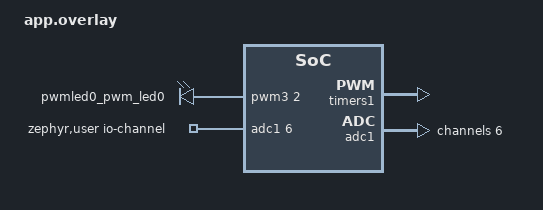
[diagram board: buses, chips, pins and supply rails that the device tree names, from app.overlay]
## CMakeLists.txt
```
cmake_minimum_required(VERSION 3.20.0)

find_package(Zephyr REQUIRED)

project(
  stm32_h7s78
  DESCRIPTION "a simple stm32h7s78_dk project ported from stm32_h743zi"
  VERSION 1
  LANGUAGES C
)

file(GLOB APP_SOURCES src/*.c)

target_sources(app PRIVATE ${APP_SOURCES})

add_subdirectory(ui)

target_link_libraries(app PRIVATE ui)

target_include_directories(app PRIVATE include)
```

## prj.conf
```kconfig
CONFIG_LV_Z_MEM_POOL_SIZE=262144
CONFIG_MAIN_STACK_SIZE=8192

CONFIG_DISPLAY=y

# display config (DK native LTDC panel, chosen via board dts)
CONFIG_LVGL=y
CONFIG_LV_USE_LABEL=y

# input config (DK native GT911 touch, chosen via board dts;
# INPUT_GT911 + interrupt mode default on when INPUT is enabled)
CONFIG_INPUT=y
CONFIG_LV_Z_POINTER_INPUT=y

CONFIG_SHELL=y
CONFIG_PRINTK=y

# picolibc: enable %f in printf/snprintf (gauge/card/slider value text)
CONFIG_PICOLIBC_IO_FLOAT=y

CONFIG_SERIAL=y
CONFIG_UART_INTERRUPT_DRIVEN=y

CONFIG_JSON_LIBRARY=y

# pwm function
CONFIG_PWM=y
CONFIG_PWM_STM32=y

CONFIG_ADC=y

CONFIG_GPIO=y
```

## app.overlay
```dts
#include "zephyr/dt-bindings/pwm/pwm.h"

/*
 * Port of stm32_h743zi app.overlay to the STM32H7S78-DK.
 *
 * Display/touch: the DK's native LTDC RGB panel (800x480) and GT911 I2C
 * touch controller are already enabled by the board dts
 * (stm32h7s78_dk-common.dtsi) with zephyr,display / zephyr,touch chosen
 * properties, so no display nodes are needed here. The ILI9341/XPT2046
 * nodes from the H743 board are dropped.
 *
 * Pin conflicts resolved vs. the H743 mapping:
 *   - tim1_ch1n PE8 -> PA7   (PE8 is uart7 TX on the DK)
 *   - tim1_ch2  PE11 -> PC3 (PE11 is ltdc_vsync on the DK)
 *   - spi4 disabled         (PE13 is needed by tim1_ch3; spi4_miso_pe13)
 */

&timers1 {
    status = "okay";
    st,countermode = <0x20>;
    st,deadtime = <255>;

    pwm1: pwm {
        status = "okay";

        pinctrl-0 = <
            &tim1_ch1_pe9
            &tim1_ch1n_pa7

            &tim1_ch2_pc3
            &tim1_ch2n_pe10

            &tim1_ch3_pe13
            &tim1_ch3n_pb1
        >;
        pinctrl-names = "default";
    };
};

/* Board enables spi4 by default (Pmod); disable it to free PE13 for TIM1 CH3 */
&spi4 {
    status = "disabled";
};

/ {
    aliases {
        /* parser.c drives this PWM from parsed UART commands;
         * referenced in code as DT_ALIAS(pwm_led0) which resolves to pwm-led0 */
        pwm-led0 = &pwmled0_pwm_led0;
    };

    pwmled0: pwmled0 {
        compatible = "pwm-leds";

        pwmled0_pwm_led0: pwm_led0 {
            /* channel 2 = TIM3_CH2 on PB5 (enabled by board dts);
             * period/pulse are overridden at runtime by parser.c */
            pwms = <&pwm3 2 PWM_MSEC(20) PWM_POLARITY_NORMAL>;
        };
    };

    zephyr,user {
        /* H7S78 has no ADC3; use ADC1 channel 6 on PF12 (Arduino A3),
         * pinctrl + adc1 node already enabled by the board dts */
        io-channels = <&adc1 6>;
    };
};

&adc1 {
    #address-cells = <1>;
    #size-cells = <0>;

    channel@6 {
        reg = <6>;
        zephyr,gain = "ADC_GAIN_1";
        zephyr,reference = "ADC_REF_INTERNAL";
        zephyr,acquisition-time = <ADC_ACQ_TIME_MAX>;
        zephyr,resolution = <12>;
    };
};
```

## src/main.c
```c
#include <zephyr/kernel.h>
#include <zephyr/drivers/display.h>
#include "ui.h"

int main(void)
{
    const struct device *display_dev = DEVICE_DT_GET(DT_CHOSEN(zephyr_display));
    create_ui();
    display_blanking_off(display_dev);

    // update ui screen
    while (1) {
        lv_timer_handler();
        k_sleep(K_MSEC(100));
    }
}
```
